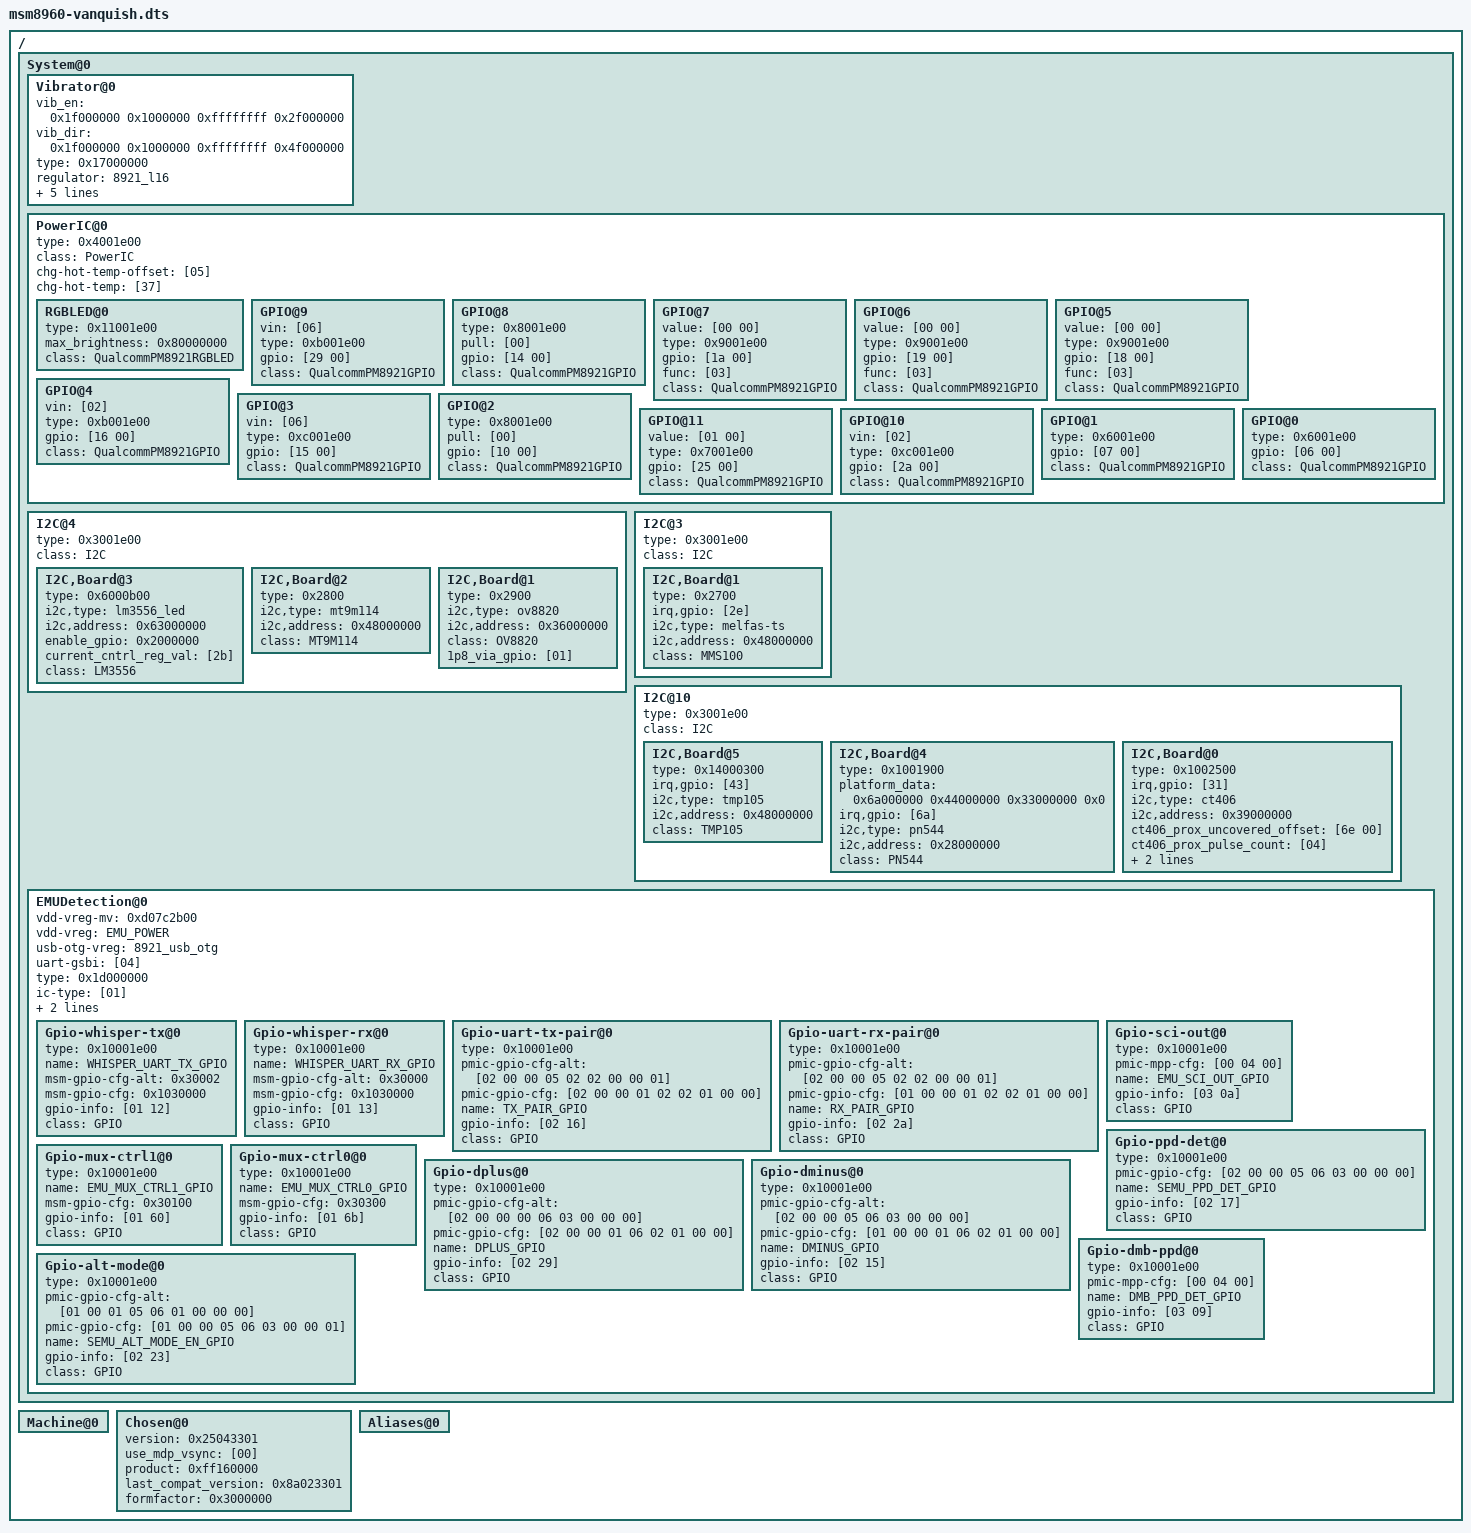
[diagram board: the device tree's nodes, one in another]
/dts-v1/;

/ {

	System@0 {

		Vibrator@0 {
			vib_en = <0x1f000000 0x1000000 0xffffffff 0x2f000000>;
			vib_dir = <0x1f000000 0x1000000 0xffffffff 0x4f000000>;
			type = <0x17000000>;
			regulator = "8921_l16";
			pwm = <0x1f4e0000 0x1000000 0x1000000 0x1000000 0xa7610000 0xe8800000 0xe8800000 0x204e0000 0xe7800000 0x409c0000 0x409c0000 0xa8610000 0x3f9c0000 0x20cb0000 0x20cb0000 0xe8800000 0x60ea0000 0x60ea0000 0x60ea0000 0x409c0000 0x4181ba01 0x409c0000 0x4c9a0000 0x409c0000 0x2985ba01 0x10270000 0x10270000 0x88130000 0x80c3c901 0x409c0000 0x4c9a0000 0x0>;
			min = <0x983a0000>;
			max = <0x80c3c901>;
			class = "Vibrator";
		};

		PowerIC@0 {
			type = <0x4001e00>;
			class = "PowerIC";
			chg-hot-temp-offset = [05];
			chg-hot-temp = [37];

			RGBLED@0 {
				type = <0x11001e00>;
				max_brightness = <0x80000000>;
				class = "QualcommPM8921RGBLED";
			};

			GPIO@9 {
				vin = [06];
				type = <0xb001e00>;
				gpio = [29 00];
				class = "QualcommPM8921GPIO";
			};

			GPIO@8 {
				type = <0x8001e00>;
				pull = [00];
				gpio = [14 00];
				class = "QualcommPM8921GPIO";
			};

			GPIO@7 {
				value = [00 00];
				type = <0x9001e00>;
				gpio = [1a 00];
				func = [03];
				class = "QualcommPM8921GPIO";
			};

			GPIO@6 {
				value = [00 00];
				type = <0x9001e00>;
				gpio = [19 00];
				func = [03];
				class = "QualcommPM8921GPIO";
			};

			GPIO@5 {
				value = [00 00];
				type = <0x9001e00>;
				gpio = [18 00];
				func = [03];
				class = "QualcommPM8921GPIO";
			};

			GPIO@4 {
				vin = [02];
				type = <0xb001e00>;
				gpio = [16 00];
				class = "QualcommPM8921GPIO";
			};

			GPIO@3 {
				vin = [06];
				type = <0xc001e00>;
				gpio = [15 00];
				class = "QualcommPM8921GPIO";
			};

			GPIO@2 {
				type = <0x8001e00>;
				pull = [00];
				gpio = [10 00];
				class = "QualcommPM8921GPIO";
			};

			GPIO@11 {
				value = [01 00];
				type = <0x7001e00>;
				gpio = [25 00];
				class = "QualcommPM8921GPIO";
			};

			GPIO@10 {
				vin = [02];
				type = <0xc001e00>;
				gpio = [2a 00];
				class = "QualcommPM8921GPIO";
			};

			GPIO@1 {
				type = <0x6001e00>;
				gpio = [07 00];
				class = "QualcommPM8921GPIO";
			};

			GPIO@0 {
				type = <0x6001e00>;
				gpio = [06 00];
				class = "QualcommPM8921GPIO";
			};
		};

		I2C@4 {
			type = <0x3001e00>;
			class = "I2C";

			I2C,Board@3 {
				type = <0x6000b00>;
				i2c,type = "lm3556_led";
				i2c,address = <0x63000000>;
				enable_gpio = <0x2000000>;
				current_cntrl_reg_val = [2b];
				class = "LM3556";
			};

			I2C,Board@2 {
				type = <0x2800>;
				i2c,type = "mt9m114";
				i2c,address = <0x48000000>;
				class = "MT9M114";
			};

			I2C,Board@1 {
				type = <0x2900>;
				i2c,type = "ov8820";
				i2c,address = <0x36000000>;
				class = "OV8820";
				1p8_via_gpio = [01];
			};
		};

		I2C@3 {
			type = <0x3001e00>;
			class = "I2C";

			I2C,Board@1 {
				type = <0x2700>;
				irq,gpio = [2e];
				i2c,type = "melfas-ts";
				i2c,address = <0x48000000>;
				class = "MMS100";
			};
		};

		I2C@10 {
			type = <0x3001e00>;
			class = "I2C";

			I2C,Board@5 {
				type = <0x14000300>;
				irq,gpio = [43];
				i2c,type = "tmp105";
				i2c,address = <0x48000000>;
				class = "TMP105";
			};

			I2C,Board@4 {
				type = <0x1001900>;
				platform_data = <0x6a000000 0x44000000 0x33000000 0x0>;
				irq,gpio = [6a];
				i2c,type = "pn544";
				i2c,address = <0x28000000>;
				class = "PN544";
			};

			I2C,Board@0 {
				type = <0x1002500>;
				irq,gpio = [31];
				i2c,type = "ct406";
				i2c,address = <0x39000000>;
				ct406_prox_uncovered_offset = [6e 00];
				ct406_prox_pulse_count = [04];
				ct406_prox_covered_offset = [96 00];
				class = "CT406";
			};
		};

		EMUDetection@0 {
			vdd-vreg-mv = <0xd07c2b00>;
			vdd-vreg = "EMU_POWER";
			usb-otg-vreg = "8921_usb_otg";
			uart-gsbi = [04];
			type = <0x1d000000>;
			ic-type = [01];
			class = "Qualcomm_EMU_Detection";
			accy-support = [00];

			Gpio-whisper-tx@0 {
				type = <0x10001e00>;
				name = "WHISPER_UART_TX_GPIO";
				msm-gpio-cfg-alt = <0x30002>;
				msm-gpio-cfg = <0x1030000>;
				gpio-info = [01 12];
				class = "GPIO";
			};

			Gpio-whisper-rx@0 {
				type = <0x10001e00>;
				name = "WHISPER_UART_RX_GPIO";
				msm-gpio-cfg-alt = <0x30000>;
				msm-gpio-cfg = <0x1030000>;
				gpio-info = [01 13];
				class = "GPIO";
			};

			Gpio-uart-tx-pair@0 {
				type = <0x10001e00>;
				pmic-gpio-cfg-alt = [02 00 00 05 02 02 00 00 01];
				pmic-gpio-cfg = [02 00 00 01 02 02 01 00 00];
				name = "TX_PAIR_GPIO";
				gpio-info = [02 16];
				class = "GPIO";
			};

			Gpio-uart-rx-pair@0 {
				type = <0x10001e00>;
				pmic-gpio-cfg-alt = [02 00 00 05 02 02 00 00 01];
				pmic-gpio-cfg = [01 00 00 01 02 02 01 00 00];
				name = "RX_PAIR_GPIO";
				gpio-info = [02 2a];
				class = "GPIO";
			};

			Gpio-sci-out@0 {
				type = <0x10001e00>;
				pmic-mpp-cfg = [00 04 00];
				name = "EMU_SCI_OUT_GPIO";
				gpio-info = [03 0a];
				class = "GPIO";
			};

			Gpio-ppd-det@0 {
				type = <0x10001e00>;
				pmic-gpio-cfg = [02 00 00 05 06 03 00 00 00];
				name = "SEMU_PPD_DET_GPIO";
				gpio-info = [02 17];
				class = "GPIO";
			};

			Gpio-mux-ctrl1@0 {
				type = <0x10001e00>;
				name = "EMU_MUX_CTRL1_GPIO";
				msm-gpio-cfg = <0x30100>;
				gpio-info = [01 60];
				class = "GPIO";
			};

			Gpio-mux-ctrl0@0 {
				type = <0x10001e00>;
				name = "EMU_MUX_CTRL0_GPIO";
				msm-gpio-cfg = <0x30300>;
				gpio-info = [01 6b];
				class = "GPIO";
			};

			Gpio-dplus@0 {
				type = <0x10001e00>;
				pmic-gpio-cfg-alt = [02 00 00 00 06 03 00 00 00];
				pmic-gpio-cfg = [02 00 00 01 06 02 01 00 00];
				name = "DPLUS_GPIO";
				gpio-info = [02 29];
				class = "GPIO";
			};

			Gpio-dminus@0 {
				type = <0x10001e00>;
				pmic-gpio-cfg-alt = [02 00 00 05 06 03 00 00 00];
				pmic-gpio-cfg = [01 00 00 01 06 02 01 00 00];
				name = "DMINUS_GPIO";
				gpio-info = [02 15];
				class = "GPIO";
			};

			Gpio-dmb-ppd@0 {
				type = <0x10001e00>;
				pmic-mpp-cfg = [00 04 00];
				name = "DMB_PPD_DET_GPIO";
				gpio-info = [03 09];
				class = "GPIO";
			};

			Gpio-alt-mode@0 {
				type = <0x10001e00>;
				pmic-gpio-cfg-alt = [01 00 01 05 06 01 00 00 00];
				pmic-gpio-cfg = [01 00 00 05 06 03 00 00 01];
				name = "SEMU_ALT_MODE_EN_GPIO";
				gpio-info = [02 23];
				class = "GPIO";
			};
		};
	};

	Machine@0 {
	};

	Chosen@0 {
		version = <0x25043301>;
		use_mdp_vsync = [00];
		product = <0xff160000>;
		last_compat_version = <0x8a023301>;
		formfactor = <0x3000000>;
	};

	Aliases@0 {
	};
};
